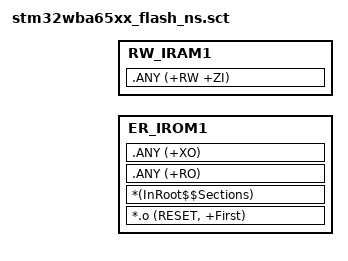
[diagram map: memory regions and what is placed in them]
#! armclang --target=arm-arm-none-eabi -march=armv8-m.main -E -xc
; *************************************************************
; *** Scatter-Loading Description File generated by uVision ***
; *************************************************************
#include "appli_region_defs.h"
/*************************************************************************************************/
#define ROM_NS_START           NS_CODE_START
#define ROM_NS_SIZE            NS_CODE_SIZE

#define RAM_NS_START           NS_RAM_START  /* SRAM1 start @ */
#define RAM_NS_SIZE            NS_RAM_SIZE     /* SRAM1 448k */

/*************************************************************************************************/

LR_IROM1 ROM_NS_START ROM_NS_SIZE  {    ; load region size_region
  ER_IROM1 ROM_NS_START ROM_NS_SIZE  {  ; load address = execution address
   *.o (RESET, +First)
   *(InRoot$$Sections)
   .ANY (+RO)
   .ANY (+XO)
  }
  RW_IRAM1 RAM_NS_START RAM_NS_SIZE  {  ; RW data
   .ANY (+RW +ZI)
  }
}

